# SF32LB57x register map
File version: 1.0
CPU: CM33 r0p1, little endian, MPU, FPU, 3 interrupt priority bits
Registers are 32-bit, read-write, reset 0x0 unless marked. A register's access mark holds for its fields unless they carry their own. Offsets are from the block's base; lines under a group give offsets from that group; [hi:lo] are bit positions; {n}, {i} and the like mark numbered series; 'fields as' and 'values as' point back to an identical list; <NAME> marks a mode.

## Memory map
0x40000000 LPSYS_RCC size 0x1000
0x40001000 DMAC2 size 0x1000
0x40002000 LPSYS_MAILBOX size 0x1000
0x40003000 LPSYS_PINMUX size 0x1000
0x40004000 PATCH size 0x1000
0x40005000 USART4 size 0x1000
0x40006000 USART5 size 0x1000
0x40007000 LPSYS_SECU size 0x1000
0x40009000 BTIM3 size 0x1000
0x4000A000 BTIM4 size 0x1000
0x4000C000 PTC2 size 0x1000
0x4000F000 LPSYS_CFG size 0x1000
0x40040000 LPSYS_AON size 0x1000
0x40041000 WDT2 size 0x1000
0x40042000 LPTIM3 size 0x1000
0x40085000 CRC2 size 0x1000
0x50000000 HPSYS_RCC size 0x1000
0x50002000 HPSYS_SECU size 0x1000
0x50003000 HPSYS_PINMUX size 0x1000
0x50004000 ATIM1 size 0x1000
0x50005000 ATIM2 size 0x1000
0x50006000 EZIP1 size 0x1000
0x50007000 EPIC size 0x1000
0x50008000 LCDC1 size 0x1000
0x50009000 I2S1 size 0x1000
0x5000A000 CAN1 size 0x1000
0x5000B000 HPSYS_CFG size 0x1000
0x5000C000 EFUSEC size 0x1000
0x5000D000 AES size 0x1000
0x5000E000 CAN2 size 0x1000
0x5000F000 TRNG size 0x1000
0x50040000 DCMI size 0x1000
0x50041000 MPI1 size 0x1000
0x50042000 MPI2 size 0x1000
0x50043000 MPI3 size 0x1000
0x50045000 SDMMC1 size 0x1000
0x50046000 SDMMC2 size 0x1000
0x50047000 USBC size 0x1000
0x50048000 CRC1 size 0x1000
0x50081000 GPDMA size 0x1000
0x50082000 HPSYS_MAILBOX size 0x1000
0x50084000 USART1 size 0x1000
0x50085000 USART2 size 0x1000
0x50086000 USART3 size 0x1000
0x50087000 AUDPRC size 0x1000
0x50088000 AUDCODEC size 0x1000
0x50089000 TSEN size 0x1000
0x5008A000 I2S2 size 0x1000
0x50090000 GPTIM1 size 0x1000
0x50092000 BTIM1 size 0x1000
0x50094000 WDT1 size 0x1000
0x50095000 SPI1 size 0x1000
0x50096000 SPI2 size 0x1000
0x5009A000 PDM1 size 0x1000
0x5009B000 PDM2 size 0x1000
0x5009C000 I2C1 size 0x1000
0x5009D000 I2C2 size 0x1000
0x5009E000 I2C3 size 0x1000
0x5009F000 I2C4 size 0x1000
0x500A0000 HPSYS_GPIO size 0x1000
0x500A1000 PTM1 size 0x1000
0x500B0000 GPTIM2 size 0x1000
0x500B1000 BTIM2 size 0x1000
0x500B2000 GPADC size 0x1000
0x500B3000 PWM1 size 0x1000
0x500C0000 HPSYS_AON size 0x1000
0x500C1000 LPTIM1 size 0x1000
0x500C2000 LPTIM2 size 0x1000
0x500CA000 PMUC size 0x1000
0x500CB000 RTC size 0x1000
0x500CC000 IWDT size 0x1000

## HPSYS_PINMUX
Base 0x50003000
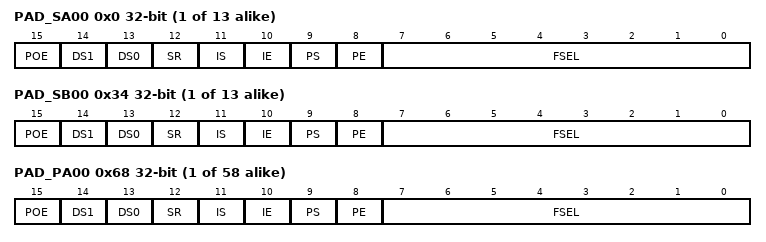
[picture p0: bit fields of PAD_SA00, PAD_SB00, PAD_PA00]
{0x0+4i} PAD_SA{i:02} (i=0..12)
  [15] POE — Reserved. Always set to logic LOW
  [14] DS1 — Drive Select 1. Used to select output drive strength
  [13] DS0 — Drive Select 0. Used to select output drive strength
  [12] SR — Slew Rate. Logic HIGH selects slow slew rate, logic LOW selects fast slew rate
  [11] IS — Input Select. Logic LOW selects CMOS input, logic HIGH selects Schmitt input
  [10] IE — Input Enable. Logic HIGH enables the input buffer
  [9] PS — Pull Select. Logic HIGH selects pull-up, logic LOW select pull-down
  [8] PE — Pull Enable. Logic HIGH enables week pull device
  [7:0] FSEL — Function Select
{0x34+4i} PAD_SB{i:02} (i=0..12)
  fields as PAD_SA00
{0x68+4i} PAD_PA{i:02} (i=0..57)
  fields as PAD_SA00

## EFUSEC
Base 0x5000C000
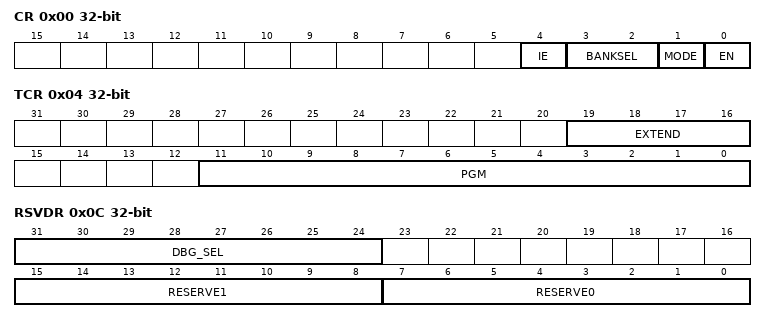
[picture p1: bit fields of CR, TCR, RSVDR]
0x00 CR — Control Register
  [4] IE — Interrupt enable
  [3:2] BANKSEL — Bank select
  [1] MODE — 0 - READ, 1 - PGM
  [0] EN — Write 1 to enable PGM/READ. Self clear
0x04 TCR — Timing Control Register
  [19:16] EXTEND — extend time for other timing except PGM
  [11:0] PGM — PGM time
0x08 SR — Status Register
  [0] DONE — Indicates PGM/READ done. Write 1 to clear
0x0C RSVDR — Reserved Register
  [31:24] DBG_SEL, [15:8] RESERVE1, [7:0] RESERVE0
{0x10+4i} PGM_DATA{i} (i=0..7) — Program Data{i}
  [31:0] DATA
{0x30+4i} BANK0_DATA{i} (i=0..7)
  [31:0] DATA
{0x50+4i} BANK1_DATA{i} (i=0..7)
  [31:0] DATA
{0x70+4i} BANK2_DATA{i} (i=0..7)
  [31:0] DATA
